# SF32LB57x register map
File version: 1.0
CPU: CM33 r0p1, little endian, MPU, FPU, 3 interrupt priority bits
Registers are 32-bit, read-write, reset 0x0 unless marked. A register's access mark holds for its fields unless they carry their own. Offsets are from the block's base; [hi:lo] are bit positions; 'fields as' and 'values as' point back to an identical list.

## LPSYS_AON
Base 0x40040000
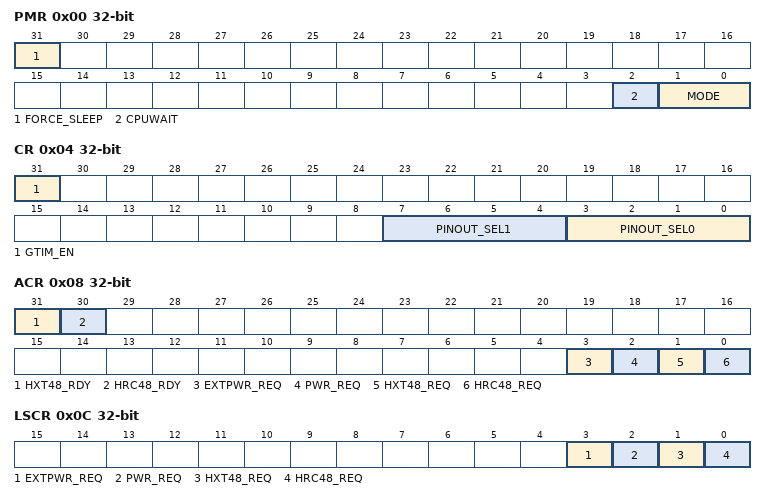
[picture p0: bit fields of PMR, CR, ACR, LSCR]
0x00 PMR — Power Mode Register
  [31] FORCE_SLEEP — force to enter low power mode (for debug only)
  [2] CPUWAIT — Stall CPU out of reset
  [1:0] MODE — Power Mode: 2'h0 - active/idle; 2'h1 - light sleep; 2'h2 - deep sleep; 2'h3 - standby
0x04 CR — Control Register
  [31] GTIM_EN — Enable global timer
  [7:4] PINOUT_SEL1
  [3:0] PINOUT_SEL0 — Select output signal to VDD_AON. LSB 3-bit valid
0x08 ACR — Active Mode Control register
  [31] HXT48_RDY
  [30] HRC48_RDY
  [3] EXTPWR_REQ — Request power supply for HPSYS upon wakeup. It can help reduce HPSYS wakeup time
  [2] PWR_REQ — Request power supply for LPSYS itself
  [1] HXT48_REQ — Request HXT48 during active mode
  [0] HRC48_REQ — Request HRC48 during active mode
0x0C LSCR — Light Sleep Ctrl Register
  [3] EXTPWR_REQ — Request power supply for HPSYS upon wakeup. It can help reduce HPSYS wakeup time
  [2] PWR_REQ — Request power supply for LPSYS itself
  [1] HXT48_REQ — Request HXT48 during active mode
  [0] HRC48_REQ — Request HRC48 during active mode
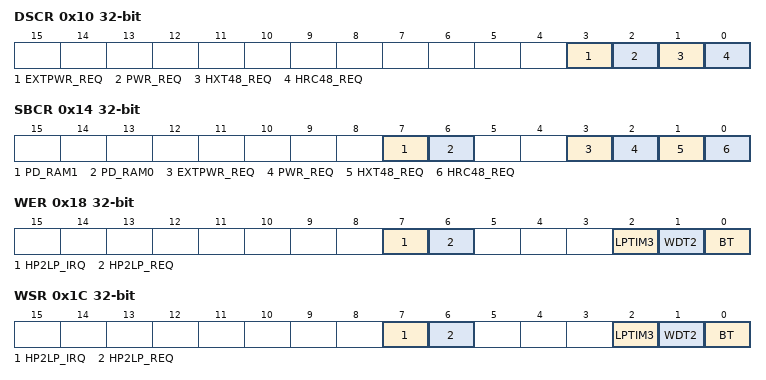
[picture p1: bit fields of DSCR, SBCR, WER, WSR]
0x10 DSCR — Deep Sleep Ctrl Register
  fields as LSCR
0x14 SBCR — Standby Mode Ctrl Register
  [7] PD_RAM1
  [6] PD_RAM0 — Power down RAM0 during Standby Mode
  [3] EXTPWR_REQ — Request power supply for HPSYS upon wakeup. It can help reduce HPSYS wakeup time
  [2] PWR_REQ — Request power supply for LPSYS itself
  [1] HXT48_REQ — Request HXT48 during active mode
  [0] HRC48_REQ — Request HRC48 during active mode
0x18 WER — Wakeup Enable register
  [7] HP2LP_IRQ
  [6] HP2LP_REQ
  [2] LPTIM3
  [1] WDT2 — Set 1 to enable WDT2 as wakeup source
  [0] BT — Set 1 to enable BT timer as wakeup source
0x1C WSR — Wakeup Status register
  [7] HP2LP_IRQ
  [6] HP2LP_REQ
  [2] LPTIM3
  [1] WDT2 — Indicates the wakeup status from WDT2. Note: the status is masked by WER
  [0] BT — Indicates the wakeup status from BT timer. Note: the status is masked by WER
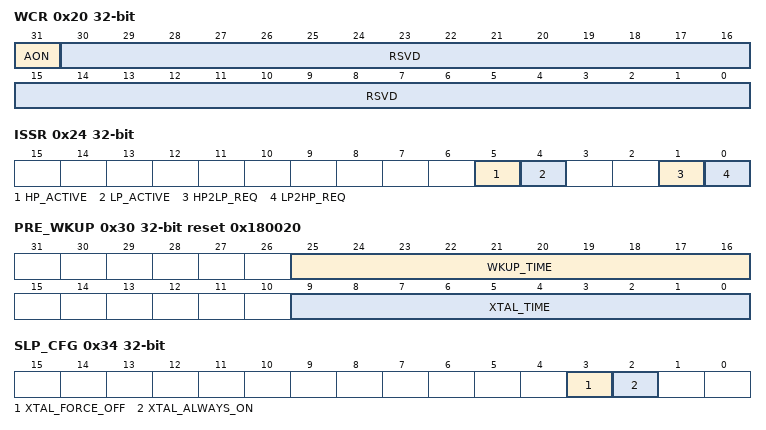
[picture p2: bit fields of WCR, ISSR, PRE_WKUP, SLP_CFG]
0x20 WCR — Wakeup Clear register
  [31] AON — Write 1 to clear the AON wakeup IRQ status
  [30:0] RSVD — Note: clear the wakeup status directly in the corresponding module
0x24 ISSR — Inter System Status Register
  [5] HP_ACTIVE — 1 indicates HP system is active
  [4] LP_ACTIVE
  [1] HP2LP_REQ
  [0] LP2HP_REQ — Set REQ bit and wait for several cycles, then check HP active status. It forces HP to stay in active mode
0x28 TARGET — BT sleep time target
  [27:0] SLEEP_TARGET — bt sleep time target in cycles of low power clock. Max sleep time is about 2.3 hours in 32.768kHz
0x2C ACTUAL — BT actual sleep time
  [27:0] SLEEP_CNT — bt actual sleep time in cycles of low power clock. If not woken up by software or external interrupt, sleep_cnt counts up every low power clock cycle, until reaches sleep_target
0x30 PRE_WKUP reset 0x180020 — time before bt awake
  [25:16] WKUP_TIME — cycles of low power clock for bt system ready before bt awake. Max time is about 31ms in 32.768kHz
  [9:0] XTAL_TIME — cycles of low power clock for xtal ready before bt awake. Max time is about 31ms in 32.768kHz
0x34 SLP_CFG — BT sleep configuration
  [3] XTAL_FORCE_OFF — xtal_req is forced low
  [2] XTAL_ALWAYS_ON — xtal_req will be always high except be forced off
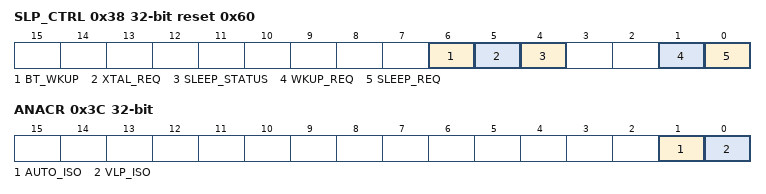
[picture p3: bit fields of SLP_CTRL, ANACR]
0x38 SLP_CTRL reset 0x60 — BT sleep control
  [6] BT_WKUP — bt wakeup source. 1 means bt has not enter sleep or has enter wakeup procedure
  [5] XTAL_REQ — xtal request status. 1 means bt is requiring xtal.
  [4] SLEEP_STATUS — bt sleep status. 1 means bt is sleeping and sleep_cnt is counting up
  [1] WKUP_REQ — software request to wakeup bt. Will be cleared automatically
  [0] SLEEP_REQ — bt sleep request. Will be cleared automatically
0x3C ANACR — Analog Control Register
  [1] AUTO_ISO
  [0] VLP_ISO — Set 1 to force off all LPSYS related analog modules, including ANAU/AUDIO/BRF etc
0x40 GTIMR — Global Timer Register
  [31:0] CNT — Global timer value. Write to restart from 0 and sync both HP and LP sides
0x44 RESERVE0 — Reserve Register 0
  [31:0] DATA
0x48 RESERVE1 — Reserve Register 1
  [31:0] DATA
0x100 SPR — Stack Pointer Register
  [31:0] SP — LCPU stack pointer address
0x104 PCR — Pointer Counter Register
  [31:0] PC — LCPU PC pointer address
